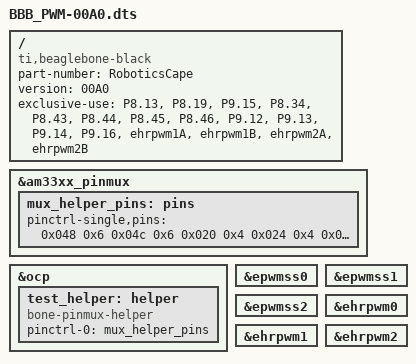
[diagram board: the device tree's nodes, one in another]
/dts-v1/;
/plugin/; 

/ {
    compatible = "ti,beaglebone-black";

    /* identification */
    part-number = "RoboticsCape";

    /* version */
    version = "00A0";
	
	exclusive-use =

		"P8.13",	/*PWM_2B*/
		"P8.19",	/*PWM_2A*/
		"P9.15",	/*MDIR_2A*/
		"P8.34",	/*MDIR_2B*/
		"P8.43",	/*MDIR_3B*/
		"P8.44",	/*MDIR_3A*/
		"P8.45",	/*MDIR_4A*/
		"P8.46",	/*MDIR_4B*/
		"P9.12",	/*MDIR_1A*/
		"P9.13",	/*MDIR_1B*/	
		"P9.14",	/*PWM_1A*/
		"P9.16",	/*PWM_1B*/



		"ehrpwm1A",
		"ehrpwm1B",
		"ehrpwm2A",
		"ehrpwm2B";



fragment@0 {
	target = <&am33xx_pinmux>;
	__overlay__ {
		/****************************************
		* 			pinmux helper				
		****************************************/
		mux_helper_pins: pins {
			pinctrl-single,pins = <
			
			/* HRPWM 1 */
			0x048  0x6 /* P9_14 | MODE 6 */
			0x04c  0x6 /* P9_16 | MODE 6 */
			 
			/* HRPWM 2 */
			0x020  0x4 /* P8_19 | MODE 4 */
			0x024  0x4 /* P8_13 | MODE 4 */


			/* GPIO Outputs
			0x090 0x0F	/*P8.7, MODE7*/
			0x094 0x0F	/*P8.8*/
			0x028 0x0F	/*P8.14*/
			0x02C 0x0F	/*P8.17*/
			0x08c 0x0F	/*P8.18*/
			0x07c 0x0F	/*P8.26*/
			0x0cc 0x0F	/*P8.34*/
			0x0C8 0x0F	/*P8.36*/
			0x0a8 0x0F	/*P8.43*/
			0x0ac 0x0F	/*P8.44*/
			0x0a0 0x0F	/*P8.45*/
			0x0a4 0x0F	/*P8.46*/
			0x078 0x0F	/*P9.12*/
			0x074 0x0F	/*P9.13*/
			0x040 0x0F	/*P9.15*/
			0x044 0x0F	/*P9.23*/
			0x19C 0x0F	/*P9.28*/
			0x1b4 0x0F	/*P9.41*/

				>;
		};
			
	};
};
	

/****************************************
	Pinmux Helper
	activates the pinmux helper list of pin modes
****************************************/
fragment@1 {
	target = <&ocp>;
		__overlay__ {
			test_helper: helper {
			compatible = "bone-pinmux-helper";
			pinctrl-names = "default";
			pinctrl-0 = <&mux_helper_pins>;
			status = "okay";
		};
	};
};

	
/****************************************
 		PWMSS			
****************************************/	
fragment@2 {
	target = <&epwmss0>;
	__overlay__ {
		status = "okay";
	};
};

fragment@3 {
	target = <&epwmss1>;
	__overlay__ {
		status = "okay";
	};
};

fragment@4 {
	target = <&epwmss2>;
	__overlay__ {
		status = "okay";
	};
};


fragment@5 {
	target = <&ehrpwm0>;
	__overlay__ {
		status = "okay";
	};
};

fragment@6 {
	target = <&ehrpwm1>;
	__overlay__ {
		status = "okay";
	};
};

fragment@7 {
	target = <&ehrpwm2>;
	__overlay__ {
		status = "okay";
	};
};

};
